# nrf5340_application register map
Vendor: Nordic Semiconductor; Series: nrf53; File version: 1
CPU: CM33 r0p4, little endian, MPU, FPU, 3 interrupt priority bits, 69 interrupts
Registers are 32-bit, read-write, reset 0x0 unless marked. A register's access mark holds for its fields unless they carry their own. Offsets are from the block's base; [hi:lo] are bit positions; {n}, {i} and the like mark numbered series.

## CC_HASH_S — CRYPTOCELL HASH engine
Base 0x50845000; alternate view of CC_AES_S
{0x640+4i} HASH_H[{i}] (i=0..7) — Description collection: HASH_H value registers. The initial HASH_H[0] register holds the least significant bits [31:0] of the value.
  [31:0] VALUE — Write the initial hash value before start of digest operation, and read the final hash value result after the digest operation has been completed.
0x684 HASH_PAD_AUTO wo — Configure the HASH engine to automatically pad data at the end of the DMA transfer to complete the digest operation.
  [0] HWPAD — Enable automatic padding in hardware.
    0=Disable (Do not enable automatic hardware padding.); 1=Enable automatic hardware padding
0x688 HASH_XOR_DIN — Perform an XOR operation of the DIN DMA engine input data being fed into the HASH engine. Set this register to '0' if XOR is not required.
  [31:0] VALUE — The value to XOR with the HASH engine input data.
0x694 HASH_INIT_STATE wo — Configure HASH engine initial state registers.
  [0] LOAD — Enable loading of data to initial state registers. Digest/IV for HASH/AES_MAC.
    0=Disable loading of data to initial state registers; 1=Enable loading of data to initial state registers
0x6A4 HASH_SELECT wo — Select HASH or GHASH engine as the digest engine to use.
  [1:0] ENGINE — Select HASH or GHASH engine as the digest engine.
    0=HASH (Select the HASH engine); 2=GHASH (Select the GHASH engine)
0x7C0 HASH_CONTROL — Control the HASH engine behavior.
  [3:0] MODE — Select HASH mode to execute
    1=SHA1 (Select SHA1 mode); 2=SHA256 (Select SHA256 mode); 10=SHA224 (Select SHA224 mode)
0x7C4 HASH_PAD reset 0x1 — Enable the hardware padding feature of the HASH engine.
  [0] ENABLE — Configure hardware padding feature.
    0=Disable hardware padding feature; 1=Enable hardware padding feature
0x7C8 HASH_PAD_FORCE — Force the hardware padding operation to trigger if the input data length is zero bytes.
  [2] ENABLE — Trigger hardware padding operation.
    0=Disable (Do not force hardware padding to trigger.); 1=Enable (Force hardware padding to trigger.)
0x7CC HASH_CUR_LEN_0 — Bits [31:0] of the number of bytes that have been digested so far.
  [31:0] VALUE — Bits [31:0] of current length of digested data in bytes.
0x7D0 HASH_CUR_LEN_1 — Bits [63:32] of the number of bytes that have been digested so far.
  [31:0] VALUE — Bits [63:32] of current length of digested data in bytes.
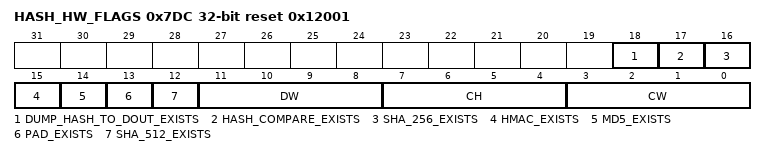
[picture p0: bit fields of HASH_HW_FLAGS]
0x7DC HASH_HW_FLAGS ro reset 0x12001 — Hardware configuration of the HASH engine. Reset value holds the supported features.
  [18] DUMP_HASH_TO_DOUT_EXISTS — If this flag is set, the engine include HASH to DOUT support.
  [17] HASH_COMPARE_EXISTS — If this flag is set, the engine include compare digest logic.
  [16] SHA_256_EXISTS — If this flag is set, the engine include SHA-256 support.
  [15] HMAC_EXISTS — If this flag is set, the engine include HMAC support.
  [14] MD5_EXISTS — If this flag is set, the engine include MD5 support.
  [13] PAD_EXISTS — If this flag is set, the engine include pad block support.
  [12] SHA_512_EXISTS — If this flag is set, the engine include SHA-512 support.
  [11:8] DW — Determine the granularity of word size.
    0=32 bits word data; 1=64 bits word data
  [7:4] CH — Indicate if Hi adders are present for each Hi value or 1 adder is shared for all Hi.
    0=One (One Hi value is updated at a time.); 1=All (All Hi values are updated at the same time.)
  [3:0] CW — Indicates the number of concurrent words the hash is using to compute signature.
    1=One (One concurrent word used by hash during signature generation); 2=Two (Two concurrent words used by hash during signature generation)
0x7E4 HASH_SW_RESET wo — Reset the HASH engine.
  [0] RESET — Writing any value to this address resets the HASH engine. The reset takes 4 CPU clock cycles to complete.
    1=Enable (Reset HASH engine.)
0x7E8 HASH_ENDIANNESS reset 0x1 — Configure the endianness of HASH data and padding generation.
  [0] ENDIAN — Endianness of HASH data and padding generation. The default value is little-endian.
    0=LittleEndian (Use little-endian format for data and padding); 1=BigEndian (Use big-endian format for data and padding)
